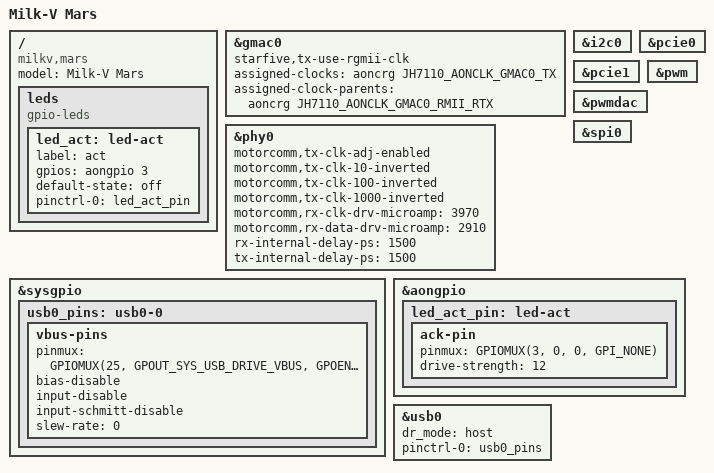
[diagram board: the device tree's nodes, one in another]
// SPDX-License-Identifier: GPL-2.0 OR MIT
/*
 * Copyright (C) 2023 Jisheng Zhang <jszhang@kernel.org>
 */

/dts-v1/;
#include "jh7110-common.dtsi"

/ {
	model = "Milk-V Mars";
	compatible = "milkv,mars", "starfive,jh7110";

	leds {
		compatible = "gpio-leds";
		led_act: led-act {
			label = "act";
			gpios = <&aongpio 3 GPIO_ACTIVE_HIGH>;
			default-state = "off";
		};
	};
};

&gmac0 {
	starfive,tx-use-rgmii-clk;
	assigned-clocks = <&aoncrg JH7110_AONCLK_GMAC0_TX>;
	assigned-clock-parents = <&aoncrg JH7110_AONCLK_GMAC0_RMII_RTX>;
	status = "okay";
};

&i2c0 {
	status = "okay";
};

&pcie0 {
	status = "okay";
};

&pcie1 {
	status = "okay";
};

&phy0 {
	motorcomm,tx-clk-adj-enabled;
	motorcomm,tx-clk-10-inverted;
	motorcomm,tx-clk-100-inverted;
	motorcomm,tx-clk-1000-inverted;
	motorcomm,rx-clk-drv-microamp = <3970>;
	motorcomm,rx-data-drv-microamp = <2910>;
	rx-internal-delay-ps = <1500>;
	tx-internal-delay-ps = <1500>;
};

&pwm {
	status = "okay";
};

&pwmdac {
	status = "okay";
};

&spi0 {
	status = "okay";
};

&sysgpio {
	usb0_pins: usb0-0 {
		vbus-pins {
			pinmux = <GPIOMUX(25, GPOUT_SYS_USB_DRIVE_VBUS,
					      GPOEN_ENABLE,
					      GPI_NONE)>;
			bias-disable;
			input-disable;
			input-schmitt-disable;
			slew-rate = <0>;
		};
	};
};

&aongpio {
	status = "okay";
	led_act_pin: led-act {
		ack-pin {
			pinmux = <GPIOMUX(3, 0, 0, GPI_NONE)>;
			drive-strength = <12>;
		};
	};
};

&led_act {
	status = "okay";
	pinctrl-names = "default";
	pinctrl-0 = <&led_act_pin>;
};

&usb0 {
	dr_mode = "host";
	pinctrl-names = "default";
	pinctrl-0 = <&usb0_pins>;
	status = "okay";
};
